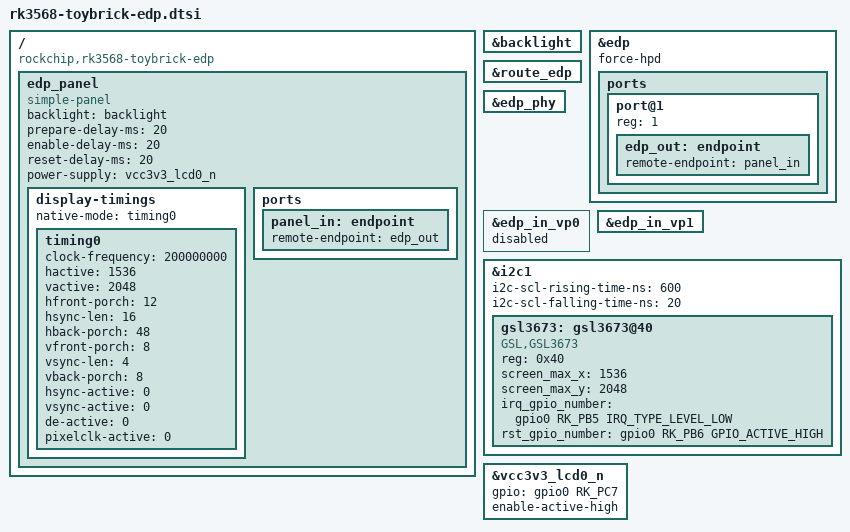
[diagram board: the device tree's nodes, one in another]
/*
 * Copyright (c) 2019 Fuzhou Rockchip Electronics Co., Ltd
 *
 * This file is dual-licensed: you can use it either under the terms
 * of the GPL or the X11 license, at your option. Note that this dual
 * licensing only applies to this file, and not this project as a
 * whole.
 *
 *  a) This file is free software; you can redistribute it and/or
 *     modify it under the terms of the GNU General Public License as
 *     published by the Free Software Foundation; either version 2 of the
 *     License, or (at your option) any later version.
 *
 *     This file is distributed in the hope that it will be useful,
 *     but WITHOUT ANY WARRANTY; without even the implied warranty of
 *     MERCHANTABILITY or FITNESS FOR A PARTICULAR PURPOSE.  See the
 *     GNU General Public License for more details.
 *
 * Or, alternatively,
 *
 *  b) Permission is hereby granted, free of charge, to any person
 *     obtaining a copy of this software and associated documentation
 *     files (the "Software"), to deal in the Software without
 *     restriction, including without limitation the rights to use,
 *     copy, modify, merge, publish, distribute, sublicense, and/or
 *     sell copies of the Software, and to permit persons to whom the
 *     Software is furnished to do so, subject to the following
 *     conditions:
 *
 *     The above copyright notice and this permission notice shall be
 *     included in all copies or substantial portions of the Software.
 *
 *     THE SOFTWARE IS PROVIDED "AS IS", WITHOUT WARRANTY OF ANY KIND,
 *     EXPRESS OR IMPLIED, INCLUDING BUT NOT LIMITED TO THE WARRANTIES
 *     OF MERCHANTABILITY, FITNESS FOR A PARTICULAR PURPOSE AND
 *     NONINFRINGEMENT. IN NO EVENT SHALL THE AUTHORS OR COPYRIGHT
 *     HOLDERS BE LIABLE FOR ANY CLAIM, DAMAGES OR OTHER LIABILITY,
 *     WHETHER IN AN ACTION OF CONTRACT, TORT OR OTHERWISE, ARISING
 *     FROM, OUT OF OR IN CONNECTION WITH THE SOFTWARE OR THE USE OR
 *     OTHER DEALINGS IN THE SOFTWARE.
 */

/ {
	compatible = "rockchip,rk3568-toybrick-edp", "rockchip,rk3568";

	edp_panel: edp_panel {
		compatible = "simple-panel";
		backlight = <&backlight>;
		prepare-delay-ms = <20>;
		enable-delay-ms = <20>;
		reset-delay-ms = <20>;

		display-timings {
			native-mode = <&timing0>;

			timing0: timing0 {
				clock-frequency = <200000000>;
				hactive = <1536>;
				vactive = <2048>;
				hfront-porch = <12>;
				hsync-len = <16>;
				hback-porch = <48>;
				vfront-porch = <8>;
				vsync-len = <4>;
				vback-porch = <8>;
				hsync-active = <0>;
				vsync-active = <0>;
				de-active = <0>;
				pixelclk-active = <0>;
			};
		};

		ports {
			panel_in: endpoint {
				remote-endpoint = <&edp_out>;
			};
		};
	};

};


&backlight {
	status = "okay";
};

&edp {
	status = "okay";
	force-hpd;

	ports {
		port@1 {
			reg = <1>;

			edp_out: endpoint {
				remote-endpoint = <&panel_in>;
			};
		};
	};

};

&route_edp {
	status = "okay";
};

&edp_phy {
	status = "okay";
};

&edp_in_vp0 {
	status = "disabled";
};

&edp_in_vp1 {
	status = "okay";
};

&edp_panel {
	power-supply = <&vcc3v3_lcd0_n>;
};

&i2c1 {
        status = "okay";
        i2c-scl-rising-time-ns = <600>;
        i2c-scl-falling-time-ns = <20>;	
        gsl3673: gsl3673@40 {
				status = "okay";
                compatible = "GSL,GSL3673";
                reg = <0x40>;
                screen_max_x = <1536>;
                screen_max_y = <2048>;
                irq_gpio_number = <&gpio0 RK_PB5 IRQ_TYPE_LEVEL_LOW>;
                rst_gpio_number = <&gpio0 RK_PB6 GPIO_ACTIVE_HIGH>;
        };	
};

&vcc3v3_lcd0_n {
	gpio = <&gpio0 RK_PC7 GPIO_ACTIVE_HIGH>;
	enable-active-high;
};
